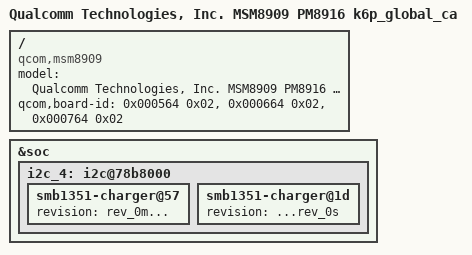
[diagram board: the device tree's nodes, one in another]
/* Copyright (c) 2014, The Linux Foundation. All rights reserved.
 *
 * This program is free software; you can redistribute it and/or modify
 * it under the terms of the GNU General Public License version 2 and
 * only version 2 as published by the Free Software Foundation.
 *
 * This program is distributed in the hope that it will be useful,
 * but WITHOUT ANY WARRANTY; without even the implied warranty of
 * MERCHANTABILITY or FITNESS FOR A PARTICULAR PURPOSE.  See the
 * GNU General Public License for more details.
 */

/dts-v1/;

#include "msm8909-k6p_global_ca.dtsi"
#include "../../qcom/msm8909-pm8916.dtsi"
#include "msm8909-pm8916-k6p_global_ca.dtsi"

/ {
	model = "Qualcomm Technologies, Inc. MSM8909 PM8916 k6p_global_ca";
	compatible = "qcom,msm8909";
	qcom,board-id= <0x000564 0x02>, /* rev_a1   | LGE_PLATFORM_ID(0x64), LGE_SUBTYPE=(0:PM8909, 2:PM8916) */
	               <0x000664 0x02>, /* rev_1_0 | LGE_PLATFORM_ID(0x64), LGE_SUBTYPE=(0:PM8909, 2:PM8916) */
	               <0x000764 0x02>; /* rev_1_1 | LGE_PLATFORM_ID(0x64), LGE_SUBTYPE=(0:PM8909, 2:PM8916) */
};

&soc {
	i2c_4: i2c@78b8000 { /* BLSP4 : BLSP4 QUP3 */
		status = "ok";

		smb1351-charger@57 {
			revision = "rev_0m...";
			status = "ok";
		};
		smb1351-charger@1d {
			revision = "...rev_0s";
			status = "ok";
		};
	};
};
